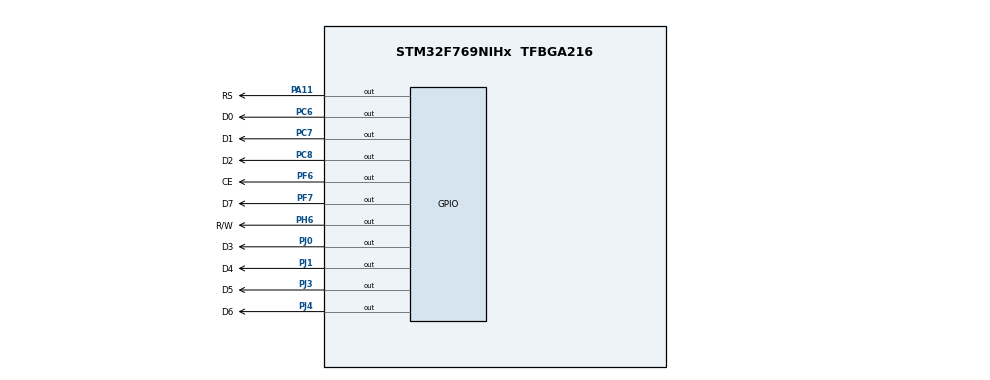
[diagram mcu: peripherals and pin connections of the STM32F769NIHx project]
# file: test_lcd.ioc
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Mcu.Family=STM32F7
Mcu.Name=STM32F769NIHx
Mcu.Package=TFBGA216
NVIC.PriorityGroup=NVIC_PRIORITYGROUP_4
PA11.GPIO_Label=RS
PA11.Signal=GPIO_Output
PC6.GPIO_Label=D0
PC6.Signal=GPIO_Output
PC7.GPIO_Label=D1
PC7.Signal=GPIO_Output
PC8.GPIO_Label=D2
PC8.Signal=GPIO_Output
PF6.GPIO_Label=CE
PF6.Signal=GPIO_Output
PF7.GPIO_Label=D7
PF7.Signal=GPIO_Output
PH6.GPIO_Label=R/W
PH6.Signal=GPIO_Output
PJ0.GPIO_Label=D3
PJ0.Signal=GPIO_Output
PJ1.GPIO_Label=D4
PJ1.Signal=GPIO_Output
PJ3.GPIO_Label=D5
PJ3.Signal=GPIO_Output
PJ4.GPIO_Label=D6
PJ4.Signal=GPIO_Output
ProjectManager.HeapSize=0x200
ProjectManager.StackSize=0x400
ProjectManager.TargetToolchain=STM32CubeIDE
RCC.AHBCLKDivider=RCC_SYSCLK_DIV2
RCC.AHBFreq_Value=8000000
RCC.APB1Freq_Value=8000000
RCC.APB1TimFreq_Value=8000000
RCC.APB2Freq_Value=8000000
RCC.APB2TimFreq_Value=8000000
RCC.CortexFreq_Value=8000000
RCC.HCLKFreq_Value=8000000
RCC.HSE_VALUE=25000000
RCC.HSI_VALUE=16000000
RCC.LSE_VALUE=32768
RCC.USBFreq_Value=96000000
RCC.VCOOutputFreq_Value=192000000
board=custom

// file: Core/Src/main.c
/* USER CODE BEGIN Header */
/**
  ******************************************************************************
  * @file           : main.c
  * @brief          : Main program body
  ******************************************************************************
  * @attention
  *
  * <h2><center>&copy; Copyright (c) 2021 STMicroelectronics.
  * All rights reserved.</center></h2>
  *
  * This software component is licensed by ST under BSD 3-Clause license,
  * the "License"; You may not use this file except in compliance with the
  * License. You may obtain a copy of the License at:
  *                        opensource.org/licenses/BSD-3-Clause
  *
  ******************************************************************************
  */
/* USER CODE END Header */
#include "main.h"

/* USER CODE BEGIN Includes */
#include "LCD.h"
/* USER CODE END Includes */

void SystemClock_Config(void);
static void MX_GPIO_Init(void);

int main(void)
{

  /* MCU Configuration--------------------------------------------------------*/

  /* Reset of all peripherals, Initializes the Flash interface and the Systick. */
  HAL_Init();

  /* Configure the system clock */
  SystemClock_Config();

  /* Initialize all configured peripherals */
  MX_GPIO_Init();
  /* USER CODE BEGIN 2 */
  LCD_t lcd;

  const char string[] = "Hello";

  GPIO_TypeDef *dataPorts[] = {D0_GPIO_Port, D1_GPIO_Port, D2_GPIO_Port, D3_GPIO_Port, D4_GPIO_Port, D5_GPIO_Port, D6_GPIO_Port, D7_GPIO_Port };
  uint16_t dataPins[]       = {D0_Pin, D1_Pin, D2_Pin, D3_Pin, D4_Pin, D5_Pin, D6_Pin, D7_Pin};

  lcd = LCD_create(RS_GPIO_Port, RS_Pin,
				   R_W_GPIO_Port, R_W_Pin,
  				   CE_GPIO_Port, CE_Pin,
  				   dataPorts,    dataPins);

  LCD_init(&lcd);

  LCD_write_string(&lcd, string);
  /* USER CODE END 2 */

  /* Infinite loop */
  while (1)
  {

  }
}

void SystemClock_Config(void)
{
  RCC_OscInitTypeDef RCC_OscInitStruct = {0};
  RCC_ClkInitTypeDef RCC_ClkInitStruct = {0};

  /** Configure the main internal regulator output voltage
  */
  __HAL_RCC_PWR_CLK_ENABLE();
  __HAL_PWR_VOLTAGESCALING_CONFIG(PWR_REGULATOR_VOLTAGE_SCALE3);
  /** Initializes the RCC Oscillators according to the specified parameters
  * in the RCC_OscInitTypeDef structure.
  */
  RCC_OscInitStruct.OscillatorType = RCC_OSCILLATORTYPE_HSI;
  RCC_OscInitStruct.HSIState = RCC_HSI_ON;
  RCC_OscInitStruct.HSICalibrationValue = RCC_HSICALIBRATION_DEFAULT;
  RCC_OscInitStruct.PLL.PLLState = RCC_PLL_NONE;
  if (HAL_RCC_OscConfig(&RCC_OscInitStruct) != HAL_OK)
  {
    Error_Handler();
  }
  /** Initializes the CPU, AHB and APB buses clocks
  */
  RCC_ClkInitStruct.ClockType = RCC_CLOCKTYPE_HCLK|RCC_CLOCKTYPE_SYSCLK
                              |RCC_CLOCKTYPE_PCLK1|RCC_CLOCKTYPE_PCLK2;
  RCC_ClkInitStruct.SYSCLKSource = RCC_SYSCLKSOURCE_HSI;
  RCC_ClkInitStruct.AHBCLKDivider = RCC_SYSCLK_DIV2;
  RCC_ClkInitStruct.APB1CLKDivider = RCC_HCLK_DIV1;
  RCC_ClkInitStruct.APB2CLKDivider = RCC_HCLK_DIV1;

  if (HAL_RCC_ClockConfig(&RCC_ClkInitStruct, FLASH_LATENCY_0) != HAL_OK)
  {
    Error_Handler();
  }
}

static void MX_GPIO_Init(void)
{
  GPIO_InitTypeDef GPIO_InitStruct = {0};

  /* GPIO Ports Clock Enable */
  __HAL_RCC_GPIOA_CLK_ENABLE();
  __HAL_RCC_GPIOC_CLK_ENABLE();
  __HAL_RCC_GPIOF_CLK_ENABLE();
  __HAL_RCC_GPIOJ_CLK_ENABLE();
  __HAL_RCC_GPIOH_CLK_ENABLE();

  /*Configure GPIO pin Output Level */
  HAL_GPIO_WritePin(RS_GPIO_Port, RS_Pin, GPIO_PIN_RESET);

  /*Configure GPIO pin Output Level */
  HAL_GPIO_WritePin(GPIOC, D2_Pin|D1_Pin|D0_Pin, GPIO_PIN_RESET);

  /*Configure GPIO pin Output Level */
  HAL_GPIO_WritePin(GPIOF, D7_Pin|CE_Pin, GPIO_PIN_RESET);

  /*Configure GPIO pin Output Level */
  HAL_GPIO_WritePin(GPIOJ, D6_Pin|D5_Pin|D3_Pin|D4_Pin, GPIO_PIN_RESET);

  /*Configure GPIO pin Output Level */
  HAL_GPIO_WritePin(R_W_GPIO_Port, R_W_Pin, GPIO_PIN_RESET);

  /*Configure GPIO pin : RS_Pin */
  GPIO_InitStruct.Pin = RS_Pin;
  GPIO_InitStruct.Mode = GPIO_MODE_OUTPUT_PP;
  GPIO_InitStruct.Pull = GPIO_NOPULL;
  GPIO_InitStruct.Speed = GPIO_SPEED_FREQ_LOW;
  HAL_GPIO_Init(RS_GPIO_Port, &GPIO_InitStruct);

  /*Configure GPIO pins : D2_Pin D1_Pin D0_Pin */
  GPIO_InitStruct.Pin = D2_Pin|D1_Pin|D0_Pin;
  GPIO_InitStruct.Mode = GPIO_MODE_OUTPUT_PP;
  GPIO_InitStruct.Pull = GPIO_NOPULL;
  GPIO_InitStruct.Speed = GPIO_SPEED_FREQ_LOW;
  HAL_GPIO_Init(GPIOC, &GPIO_InitStruct);

  /*Configure GPIO pins : D7_Pin CE_Pin */
  GPIO_InitStruct.Pin = D7_Pin|CE_Pin;
  GPIO_InitStruct.Mode = GPIO_MODE_OUTPUT_PP;
  GPIO_InitStruct.Pull = GPIO_NOPULL;
  GPIO_InitStruct.Speed = GPIO_SPEED_FREQ_LOW;
  HAL_GPIO_Init(GPIOF, &GPIO_InitStruct);

  /*Configure GPIO pins : D6_Pin D5_Pin D3_Pin D4_Pin */
  GPIO_InitStruct.Pin = D6_Pin|D5_Pin|D3_Pin|D4_Pin;
  GPIO_InitStruct.Mode = GPIO_MODE_OUTPUT_PP;
  GPIO_InitStruct.Pull = GPIO_NOPULL;
  GPIO_InitStruct.Speed = GPIO_SPEED_FREQ_LOW;
  HAL_GPIO_Init(GPIOJ, &GPIO_InitStruct);

  /*Configure GPIO pin : R_W_Pin */
  GPIO_InitStruct.Pin = R_W_Pin;
  GPIO_InitStruct.Mode = GPIO_MODE_OUTPUT_PP;
  GPIO_InitStruct.Pull = GPIO_NOPULL;
  GPIO_InitStruct.Speed = GPIO_SPEED_FREQ_LOW;
  HAL_GPIO_Init(R_W_GPIO_Port, &GPIO_InitStruct);

}

void Error_Handler(void)
{
  __disable_irq();
  while (1)
  {
  }
}

/************************ (C) COPYRIGHT STMicroelectronics *****END OF FILE****/
